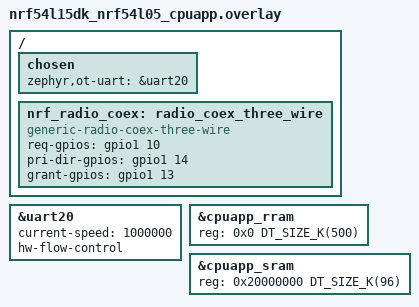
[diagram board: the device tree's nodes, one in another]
/*
 * Copyright (c) 2024 Nordic Semiconductor ASA
 *
 * SPDX-License-Identifier: LicenseRef-Nordic-5-Clause
 */

&uart20 {
	current-speed = <1000000>;
	status = "okay";
	hw-flow-control;
};

/ {
	chosen {
		zephyr,ot-uart = &uart20;
	};
};

/ {
	nrf_radio_coex: radio_coex_three_wire {
	   status = "okay";
	   compatible = "generic-radio-coex-three-wire";
	   req-gpios =     <&gpio1 10 (GPIO_ACTIVE_HIGH)>;
	   pri-dir-gpios = <&gpio1 14 (GPIO_ACTIVE_HIGH)>;
	   grant-gpios =   <&gpio1 13 (GPIO_ACTIVE_HIGH | GPIO_PULL_UP)>;
 };
};

// restore full RRAM and SRAM space - by default some parts are dedicated to FLPR
&cpuapp_rram {
	reg = <0x0 DT_SIZE_K(500)>;
};

&cpuapp_sram {
	reg = <0x20000000 DT_SIZE_K(96)>;
	ranges = <0x0 0x20000000  DT_SIZE_K(96)>;
};
